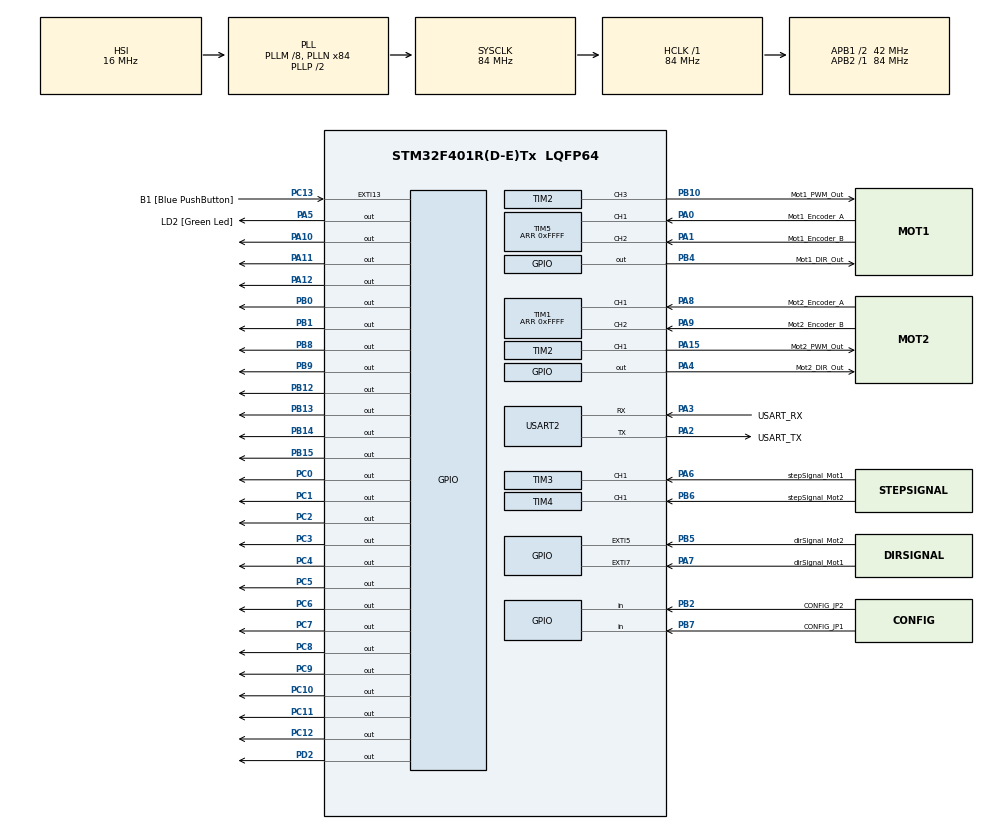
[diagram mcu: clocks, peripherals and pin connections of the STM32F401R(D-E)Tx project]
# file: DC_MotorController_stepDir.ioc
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Dma.Request0=USART2_RX
Dma.USART2_RX.0.Direction=DMA_PERIPH_TO_MEMORY
Dma.USART2_RX.0.FIFOMode=DMA_FIFOMODE_DISABLE
Dma.USART2_RX.0.Instance=DMA1_Stream5
Dma.USART2_RX.0.MemDataAlignment=DMA_MDATAALIGN_BYTE
Dma.USART2_RX.0.MemInc=DMA_MINC_ENABLE
Dma.USART2_RX.0.Mode=DMA_NORMAL
Dma.USART2_RX.0.PeriphDataAlignment=DMA_PDATAALIGN_BYTE
Dma.USART2_RX.0.PeriphInc=DMA_PINC_DISABLE
Dma.USART2_RX.0.Priority=DMA_PRIORITY_LOW
Mcu.Family=STM32F4
Mcu.Name=STM32F401R(D-E)Tx
Mcu.Package=LQFP64
NVIC.DMA1_Stream5_IRQn=true\:0\:0\:false\:false\:true\:false\:true
NVIC.EXTI9_5_IRQn=true\:0\:0\:false\:false\:false\:true\:false
NVIC.PriorityGroup=NVIC_PRIORITYGROUP_4
NVIC.TIM1_UP_TIM10_IRQn=true\:0\:0\:false\:false\:true\:false\:true
NVIC.TimeBase=TIM1_UP_TIM10_IRQn
NVIC.TimeBaseIP=TIM10
PA0-WKUP.GPIO_Label=Mot1_Encoder_A
PA0-WKUP.GPIO_PuPd=GPIO_PULLUP
PA0-WKUP.Signal=S_TIM5_CH1
PA1.GPIO_Label=Mot1_Encoder_B
PA1.GPIO_PuPd=GPIO_PULLUP
PA1.Signal=S_TIM5_CH2
PA10.GPIO_PuPd=GPIO_PULLDOWN
PA10.Signal=GPIO_Output
PA11.GPIO_PuPd=GPIO_PULLDOWN
PA11.Signal=GPIO_Output
PA12.GPIO_PuPd=GPIO_PULLDOWN
PA12.Signal=GPIO_Output
PA13.GPIO_Label=TMS
PA13.Mode=Serial_Wire
PA13.Signal=SYS_JTMS-SWDIO
PA14.GPIO_Label=TCK
PA14.Mode=Serial_Wire
PA14.Signal=SYS_JTCK-SWCLK
PA15.GPIO_Label=Mot2_PWM_Out
PA15.Signal=S_TIM2_CH1_ETR
PA2.GPIO_Label=USART_TX
PA2.GPIO_Mode=GPIO_MODE_AF_PP
PA2.GPIO_PuPd=GPIO_NOPULL
PA2.GPIO_Speed=GPIO_SPEED_FREQ_LOW
PA2.Mode=Asynchronous
PA2.Signal=USART2_TX
PA3.GPIO_Label=USART_RX
PA3.GPIO_Mode=GPIO_MODE_AF_PP
PA3.GPIO_PuPd=GPIO_NOPULL
PA3.GPIO_Speed=GPIO_SPEED_FREQ_LOW
PA3.Mode=Asynchronous
PA3.Signal=USART2_RX
PA4.GPIO_Label=Mot2_DIR_Out
PA4.Signal=GPIO_Output
PA5.GPIO_Label=LD2 [Green Led]
PA5.GPIO_Mode=GPIO_MODE_OUTPUT_PP
PA5.GPIO_PuPd=GPIO_NOPULL
PA5.GPIO_Speed=GPIO_SPEED_FREQ_LOW
PA5.Signal=GPIO_Output
PA6.GPIO_Label=stepSignal_Mot1
PA6.GPIO_PuPd=GPIO_PULLDOWN
PA6.GPIO_Speed=GPIO_SPEED_FREQ_HIGH
PA6.Signal=S_TIM3_CH1
PA7.GPIO_Label=dirSignal_Mot1
PA7.GPIO_ModeDefaultEXTI=GPIO_MODE_IT_RISING_FALLING
PA7.GPIO_PuPd=GPIO_PULLDOWN
PA7.Signal=GPXTI7
PA8.GPIO_Label=Mot2_Encoder_A
PA8.GPIO_PuPd=GPIO_PULLUP
PA8.Signal=S_TIM1_CH1
PA9.GPIO_Label=Mot2_Encoder_B
PA9.GPIO_PuPd=GPIO_PULLUP
PA9.Signal=S_TIM1_CH2
PB0.GPIO_PuPd=GPIO_PULLDOWN
PB0.Signal=GPIO_Output
PB1.GPIO_PuPd=GPIO_PULLDOWN
PB1.Signal=GPIO_Output
PB10.GPIO_Label=Mot1_PWM_Out
PB10.Signal=S_TIM2_CH3
PB12.GPIO_PuPd=GPIO_PULLDOWN
PB12.Signal=GPIO_Output
PB13.GPIO_PuPd=GPIO_PULLDOWN
PB13.Signal=GPIO_Output
PB14.GPIO_PuPd=GPIO_PULLDOWN
PB14.Signal=GPIO_Output
PB15.GPIO_PuPd=GPIO_PULLDOWN
PB15.Signal=GPIO_Output
PB2.GPIO_Label=CONFIG_JP2
PB2.GPIO_PuPd=GPIO_PULLUP
PB2.Signal=GPIO_Input
PB3.GPIO_Label=SWO
PB3.Signal=SYS_JTDO-SWO
PB4.GPIO_Label=Mot1_DIR_Out
PB4.PinState=GPIO_PIN_RESET
PB4.Signal=GPIO_Output
PB5.GPIO_Label=dirSignal_Mot2
PB5.GPIO_ModeDefaultEXTI=GPIO_MODE_IT_RISING_FALLING
PB5.GPIO_PuPd=GPIO_PULLDOWN
PB5.Signal=GPXTI5
PB6.GPIO_Label=stepSignal_Mot2
PB6.GPIO_PuPd=GPIO_PULLDOWN
PB6.GPIO_Speed=GPIO_SPEED_FREQ_HIGH
PB6.Signal=S_TIM4_CH1
PB7.GPIO_Label=CONFIG_JP1
PB7.GPIO_Mode=GPIO_MODE_INPUT
PB7.GPIO_PuPd=GPIO_PULLUP
PB7.Signal=GPIO_Input
PB8.GPIO_PuPd=GPIO_PULLDOWN
PB8.Signal=GPIO_Output
PB9.GPIO_PuPd=GPIO_PULLDOWN
PB9.Signal=GPIO_Output
PC0.GPIO_PuPd=GPIO_PULLDOWN
PC0.Signal=GPIO_Output
PC1.GPIO_PuPd=GPIO_PULLDOWN
PC1.Signal=GPIO_Output
PC10.GPIO_PuPd=GPIO_PULLDOWN
PC10.Signal=GPIO_Output
PC11.GPIO_PuPd=GPIO_PULLDOWN
PC11.Signal=GPIO_Output
PC12.GPIO_PuPd=GPIO_PULLDOWN
PC12.Signal=GPIO_Output
PC13-ANTI_TAMP.GPIO_Label=B1 [Blue PushButton]
PC13-ANTI_TAMP.GPIO_ModeDefaultEXTI=GPIO_MODE_IT_FALLING
PC13-ANTI_TAMP.GPIO_PuPd=GPIO_NOPULL
PC13-ANTI_TAMP.Signal=GPXTI13
PC14-OSC32_IN.Mode=LSE-External-Oscillator
PC14-OSC32_IN.Signal=RCC_OSC32_IN
PC15-OSC32_OUT.Mode=LSE-External-Oscillator
PC15-OSC32_OUT.Signal=RCC_OSC32_OUT
PC2.GPIO_PuPd=GPIO_PULLDOWN
PC2.Signal=GPIO_Output
PC3.GPIO_PuPd=GPIO_PULLDOWN
PC3.Signal=GPIO_Output
PC4.GPIO_PuPd=GPIO_PULLDOWN
PC4.Signal=GPIO_Output
PC5.GPIO_PuPd=GPIO_PULLDOWN
PC5.Signal=GPIO_Output
PC6.GPIO_PuPd=GPIO_PULLDOWN
PC6.Signal=GPIO_Output
PC7.GPIO_PuPd=GPIO_PULLDOWN
PC7.Signal=GPIO_Output
PC8.GPIO_PuPd=GPIO_PULLDOWN
PC8.Signal=GPIO_Output
PC9.GPIO_PuPd=GPIO_PULLDOWN
PC9.Signal=GPIO_Output
PD2.GPIO_PuPd=GPIO_PULLDOWN
PD2.Signal=GPIO_Output
PH0\ -\ OSC_IN.Mode=HSE-External-Clock-Source
PH0\ -\ OSC_IN.Signal=RCC_OSC_IN
PH1\ -\ OSC_OUT.Mode=HSE-External-Clock-Source
PH1\ -\ OSC_OUT.Signal=RCC_OSC_OUT
ProjectManager.HeapSize=0x200
ProjectManager.StackSize=0x400
ProjectManager.TargetToolchain=STM32CubeIDE
RCC.48MHZClocksFreq_Value=24000000
RCC.AHBFreq_Value=84000000
RCC.APB1CLKDivider=RCC_HCLK_DIV2
RCC.APB1Freq_Value=42000000
RCC.APB1TimFreq_Value=84000000
RCC.APB2Freq_Value=84000000
RCC.APB2TimFreq_Value=84000000
RCC.CortexFreq_Value=84000000
RCC.HCLKFreq_Value=84000000
RCC.HSE_VALUE=8000000
RCC.HSI_VALUE=16000000
RCC.PLLM=8
RCC.PLLN=84
RCC.PLLQ=7
RCC.SYSCLKFreq_VALUE=84000000
RCC.SYSCLKSource=RCC_SYSCLKSOURCE_PLLCLK
RCC.VCOOutputFreq_Value=168000000
SH.S_TIM1_CH1.0=TIM1_CH1,Encoder_Interface
SH.S_TIM1_CH2.0=TIM1_CH2,Encoder_Interface
SH.S_TIM2_CH1_ETR.0=TIM2_CH1,PWM Generation1 CH1
SH.S_TIM2_CH3.0=TIM2_CH3,PWM Generation3 CH3
SH.S_TIM3_CH1.0=TIM3_CH1,TriggerSource_TI1FP1
SH.S_TIM4_CH1.0=TIM4_CH1,TriggerSource_TI1FP1
SH.S_TIM5_CH1.0=TIM5_CH1,Encoder_Interface
SH.S_TIM5_CH2.0=TIM5_CH2,Encoder_Interface
TIM1.EncoderMode=TIM_ENCODERMODE_TI12
TIM1.IC1Filter=8
TIM1.IC2Filter=8
TIM1.Period=0xFFFF
TIM2.Channel-PWM\ Generation1\ CH1=TIM_CHANNEL_1
TIM2.Channel-PWM\ Generation3\ CH3=TIM_CHANNEL_3
TIM2.Period=1000-1
TIM2.Prescaler=4-1
TIM3.Period=0xFFFF
TIM3.Slave_TriggerFilter=11
TIM4.Period=0xFFFF
TIM4.Slave_TriggerFilter=11
TIM5.EncoderMode=TIM_ENCODERMODE_TI12
TIM5.IC1Filter=8
TIM5.IC2Filter=8
TIM5.Period=0xFFFF
USART2.VirtualMode=VM_ASYNC
VP_CRC_VS_CRC.Mode=CRC_Activate
VP_SYS_VS_tim10.Mode=TIM10
VP_TIM2_VS_ClockSourceINT.Mode=Internal
VP_TIM3_VS_ControllerModeClock.Mode=Clock Mode
VP_TIM4_VS_ControllerModeClock.Mode=Clock Mode
board=NUCLEO-F401RE

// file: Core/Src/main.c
/* USER CODE BEGIN Header */
/**
  ******************************************************************************
  * @file           : main.c
  * @brief          : Main program body
  ******************************************************************************
  * @attention
  *
  * <h2><center>&copy; Copyright (c) 2020 STMicroelectronics.
  * All rights reserved.</center></h2>
  *
  * This software component is licensed by ST under BSD 3-Clause license,
  * the "License"; You may not use this file except in compliance with the
  * License. You may obtain a copy of the License at:
  *                        opensource.org/licenses/BSD-3-Clause
  *
  ******************************************************************************
  */
/* USER CODE END Header */

#include "main.h"

/* USER CODE BEGIN Includes */
#include <motorTask.h>
//#include <dcMotorController.h>
/* USER CODE END Includes */

CRC_HandleTypeDef hcrc;

TIM_HandleTypeDef htim1;
TIM_HandleTypeDef htim2;
TIM_HandleTypeDef htim3;
TIM_HandleTypeDef htim4;
TIM_HandleTypeDef htim5;

UART_HandleTypeDef huart2;
DMA_HandleTypeDef hdma_usart2_rx;

void SystemClock_Config(void);
static void MX_GPIO_Init(void);
static void MX_DMA_Init(void);
static void MX_USART2_UART_Init(void);
static void MX_CRC_Init(void);
static void MX_TIM1_Init(void);
static void MX_TIM2_Init(void);
static void MX_TIM3_Init(void);
static void MX_TIM4_Init(void);
static void MX_TIM5_Init(void);
/* USER CODE BEGIN PFP */
void EXTI9_5_IRQHandler(void);
/* USER CODE END PFP */

int main(void)
{

  /* MCU Configuration--------------------------------------------------------*/

  /* Reset of all peripherals, Initializes the Flash interface and the Systick. */
  HAL_Init();

  /* Configure the system clock */
  SystemClock_Config();

  /* Initialize all configured peripherals */
  MX_GPIO_Init();
  MX_DMA_Init();
  MX_USART2_UART_Init();
  MX_CRC_Init();
  MX_TIM1_Init();
  MX_TIM2_Init();
  MX_TIM3_Init();
  MX_TIM4_Init();
  MX_TIM5_Init();
  /* USER CODE BEGIN 2 */
  motorInit();
  /* USER CODE END 2 */

  /* Infinite loop */
  /* USER CODE BEGIN WHILE */
  while (1)
  {
	  motorRoutine();
    /* USER CODE END WHILE */

  }
}

void SystemClock_Config(void)
{
  RCC_OscInitTypeDef RCC_OscInitStruct = {0};
  RCC_ClkInitTypeDef RCC_ClkInitStruct = {0};

  /** Configure the main internal regulator output voltage
  */
  __HAL_RCC_PWR_CLK_ENABLE();
  __HAL_PWR_VOLTAGESCALING_CONFIG(PWR_REGULATOR_VOLTAGE_SCALE2);
  /** Initializes the CPU, AHB and APB busses clocks
  */
  RCC_OscInitStruct.OscillatorType = RCC_OSCILLATORTYPE_HSI;
  RCC_OscInitStruct.HSIState = RCC_HSI_ON;
  RCC_OscInitStruct.HSICalibrationValue = RCC_HSICALIBRATION_DEFAULT;
  RCC_OscInitStruct.PLL.PLLState = RCC_PLL_ON;
  RCC_OscInitStruct.PLL.PLLSource = RCC_PLLSOURCE_HSI;
  RCC_OscInitStruct.PLL.PLLM = 8;
  RCC_OscInitStruct.PLL.PLLN = 84;
  RCC_OscInitStruct.PLL.PLLP = RCC_PLLP_DIV2;
  RCC_OscInitStruct.PLL.PLLQ = 7;
  if (HAL_RCC_OscConfig(&RCC_OscInitStruct) != HAL_OK)
  {
    Error_Handler();
  }
  /** Initializes the CPU, AHB and APB busses clocks
  */
  RCC_ClkInitStruct.ClockType = RCC_CLOCKTYPE_HCLK|RCC_CLOCKTYPE_SYSCLK
                              |RCC_CLOCKTYPE_PCLK1|RCC_CLOCKTYPE_PCLK2;
  RCC_ClkInitStruct.SYSCLKSource = RCC_SYSCLKSOURCE_PLLCLK;
  RCC_ClkInitStruct.AHBCLKDivider = RCC_SYSCLK_DIV1;
  RCC_ClkInitStruct.APB1CLKDivider = RCC_HCLK_DIV2;
  RCC_ClkInitStruct.APB2CLKDivider = RCC_HCLK_DIV1;

  if (HAL_RCC_ClockConfig(&RCC_ClkInitStruct, FLASH_LATENCY_2) != HAL_OK)
  {
    Error_Handler();
  }
}

static void MX_CRC_Init(void)
{

  hcrc.Instance = CRC;
  if (HAL_CRC_Init(&hcrc) != HAL_OK)
  {
    Error_Handler();
  }

}

static void MX_TIM1_Init(void)
{

  TIM_Encoder_InitTypeDef sConfig = {0};
  TIM_MasterConfigTypeDef sMasterConfig = {0};

  htim1.Instance = TIM1;
  htim1.Init.Prescaler = 0;
  htim1.Init.CounterMode = TIM_COUNTERMODE_UP;
  htim1.Init.Period = 0xFFFF;
  htim1.Init.ClockDivision = TIM_CLOCKDIVISION_DIV1;
  htim1.Init.RepetitionCounter = 0;
  htim1.Init.AutoReloadPreload = TIM_AUTORELOAD_PRELOAD_DISABLE;
  sConfig.EncoderMode = TIM_ENCODERMODE_TI12;
  sConfig.IC1Polarity = TIM_ICPOLARITY_RISING;
  sConfig.IC1Selection = TIM_ICSELECTION_DIRECTTI;
  sConfig.IC1Prescaler = TIM_ICPSC_DIV1;
  sConfig.IC1Filter = 8;
  sConfig.IC2Polarity = TIM_ICPOLARITY_RISING;
  sConfig.IC2Selection = TIM_ICSELECTION_DIRECTTI;
  sConfig.IC2Prescaler = TIM_ICPSC_DIV1;
  sConfig.IC2Filter = 8;
  if (HAL_TIM_Encoder_Init(&htim1, &sConfig) != HAL_OK)
  {
    Error_Handler();
  }
  sMasterConfig.MasterOutputTrigger = TIM_TRGO_RESET;
  sMasterConfig.MasterSlaveMode = TIM_MASTERSLAVEMODE_DISABLE;
  if (HAL_TIMEx_MasterConfigSynchronization(&htim1, &sMasterConfig) != HAL_OK)
  {
    Error_Handler();
  }

}

static void MX_TIM2_Init(void)
{

  TIM_ClockConfigTypeDef sClockSourceConfig = {0};
  TIM_MasterConfigTypeDef sMasterConfig = {0};
  TIM_OC_InitTypeDef sConfigOC = {0};

  htim2.Instance = TIM2;
  htim2.Init.Prescaler = 4-1;
  htim2.Init.CounterMode = TIM_COUNTERMODE_UP;
  htim2.Init.Period = 1000-1;
  htim2.Init.ClockDivision = TIM_CLOCKDIVISION_DIV1;
  htim2.Init.AutoReloadPreload = TIM_AUTORELOAD_PRELOAD_DISABLE;
  if (HAL_TIM_Base_Init(&htim2) != HAL_OK)
  {
    Error_Handler();
  }
  sClockSourceConfig.ClockSource = TIM_CLOCKSOURCE_INTERNAL;
  if (HAL_TIM_ConfigClockSource(&htim2, &sClockSourceConfig) != HAL_OK)
  {
    Error_Handler();
  }
  if (HAL_TIM_PWM_Init(&htim2) != HAL_OK)
  {
    Error_Handler();
  }
  sMasterConfig.MasterOutputTrigger = TIM_TRGO_RESET;
  sMasterConfig.MasterSlaveMode = TIM_MASTERSLAVEMODE_DISABLE;
  if (HAL_TIMEx_MasterConfigSynchronization(&htim2, &sMasterConfig) != HAL_OK)
  {
    Error_Handler();
  }
  sConfigOC.OCMode = TIM_OCMODE_PWM1;
  sConfigOC.Pulse = 0;
  sConfigOC.OCPolarity = TIM_OCPOLARITY_HIGH;
  sConfigOC.OCFastMode = TIM_OCFAST_DISABLE;
  if (HAL_TIM_PWM_ConfigChannel(&htim2, &sConfigOC, TIM_CHANNEL_1) != HAL_OK)
  {
    Error_Handler();
  }
  if (HAL_TIM_PWM_ConfigChannel(&htim2, &sConfigOC, TIM_CHANNEL_3) != HAL_OK)
  {
    Error_Handler();
  }
  HAL_TIM_MspPostInit(&htim2);

}

static void MX_TIM3_Init(void)
{

  TIM_SlaveConfigTypeDef sSlaveConfig = {0};
  TIM_MasterConfigTypeDef sMasterConfig = {0};

  htim3.Instance = TIM3;
  htim3.Init.Prescaler = 0;
  htim3.Init.CounterMode = TIM_COUNTERMODE_UP;
  htim3.Init.Period = 0xFFFF;
  htim3.Init.ClockDivision = TIM_CLOCKDIVISION_DIV1;
  htim3.Init.AutoReloadPreload = TIM_AUTORELOAD_PRELOAD_DISABLE;
  if (HAL_TIM_Base_Init(&htim3) != HAL_OK)
  {
    Error_Handler();
  }
  sSlaveConfig.SlaveMode = TIM_SLAVEMODE_EXTERNAL1;
  sSlaveConfig.InputTrigger = TIM_TS_TI1FP1;
  sSlaveConfig.TriggerPolarity = TIM_TRIGGERPOLARITY_RISING;
  sSlaveConfig.TriggerFilter = 11;
  if (HAL_TIM_SlaveConfigSynchro(&htim3, &sSlaveConfig) != HAL_OK)
  {
    Error_Handler();
  }
  sMasterConfig.MasterOutputTrigger = TIM_TRGO_RESET;
  sMasterConfig.MasterSlaveMode = TIM_MASTERSLAVEMODE_DISABLE;
  if (HAL_TIMEx_MasterConfigSynchronization(&htim3, &sMasterConfig) != HAL_OK)
  {
    Error_Handler();
  }

}

static void MX_TIM4_Init(void)
{

  TIM_SlaveConfigTypeDef sSlaveConfig = {0};
  TIM_MasterConfigTypeDef sMasterConfig = {0};

  htim4.Instance = TIM4;
  htim4.Init.Prescaler = 0;
  htim4.Init.CounterMode = TIM_COUNTERMODE_UP;
  htim4.Init.Period = 0xFFFF;
  htim4.Init.ClockDivision = TIM_CLOCKDIVISION_DIV1;
  htim4.Init.AutoReloadPreload = TIM_AUTORELOAD_PRELOAD_DISABLE;
  if (HAL_TIM_Base_Init(&htim4) != HAL_OK)
  {
    Error_Handler();
  }
  sSlaveConfig.SlaveMode = TIM_SLAVEMODE_EXTERNAL1;
  sSlaveConfig.InputTrigger = TIM_TS_TI1FP1;
  sSlaveConfig.TriggerPolarity = TIM_TRIGGERPOLARITY_RISING;
  sSlaveConfig.TriggerFilter = 11;
  if (HAL_TIM_SlaveConfigSynchro(&htim4, &sSlaveConfig) != HAL_OK)
  {
    Error_Handler();
  }
  sMasterConfig.MasterOutputTrigger = TIM_TRGO_RESET;
  sMasterConfig.MasterSlaveMode = TIM_MASTERSLAVEMODE_DISABLE;
  if (HAL_TIMEx_MasterConfigSynchronization(&htim4, &sMasterConfig) != HAL_OK)
  {
    Error_Handler();
  }

}

static void MX_TIM5_Init(void)
{

  TIM_Encoder_InitTypeDef sConfig = {0};
  TIM_MasterConfigTypeDef sMasterConfig = {0};

  htim5.Instance = TIM5;
  htim5.Init.Prescaler = 0;
  htim5.Init.CounterMode = TIM_COUNTERMODE_UP;
  htim5.Init.Period = 0xFFFF;
  htim5.Init.ClockDivision = TIM_CLOCKDIVISION_DIV1;
  htim5.Init.AutoReloadPreload = TIM_AUTORELOAD_PRELOAD_DISABLE;
  sConfig.EncoderMode = TIM_ENCODERMODE_TI12;
  sConfig.IC1Polarity = TIM_ICPOLARITY_RISING;
  sConfig.IC1Selection = TIM_ICSELECTION_DIRECTTI;
  sConfig.IC1Prescaler = TIM_ICPSC_DIV1;
  sConfig.IC1Filter = 8;
  sConfig.IC2Polarity = TIM_ICPOLARITY_RISING;
  sConfig.IC2Selection = TIM_ICSELECTION_DIRECTTI;
  sConfig.IC2Prescaler = TIM_ICPSC_DIV1;
  sConfig.IC2Filter = 8;
  if (HAL_TIM_Encoder_Init(&htim5, &sConfig) != HAL_OK)
  {
    Error_Handler();
  }
  sMasterConfig.MasterOutputTrigger = TIM_TRGO_RESET;
  sMasterConfig.MasterSlaveMode = TIM_MASTERSLAVEMODE_DISABLE;
  if (HAL_TIMEx_MasterConfigSynchronization(&htim5, &sMasterConfig) != HAL_OK)
  {
    Error_Handler();
  }

}

static void MX_USART2_UART_Init(void)
{

  huart2.Instance = USART2;
  huart2.Init.BaudRate = 115200;
  huart2.Init.WordLength = UART_WORDLENGTH_8B;
  huart2.Init.StopBits = UART_STOPBITS_1;
  huart2.Init.Parity = UART_PARITY_NONE;
  huart2.Init.Mode = UART_MODE_TX_RX;
  huart2.Init.HwFlowCtl = UART_HWCONTROL_NONE;
  huart2.Init.OverSampling = UART_OVERSAMPLING_16;
  if (HAL_UART_Init(&huart2) != HAL_OK)
  {
    Error_Handler();
  }

}

static void MX_DMA_Init(void)
{

  /* DMA controller clock enable */
  __HAL_RCC_DMA1_CLK_ENABLE();

  /* DMA interrupt init */
  /* DMA1_Stream5_IRQn interrupt configuration */
  HAL_NVIC_SetPriority(DMA1_Stream5_IRQn, 0, 0);
  HAL_NVIC_EnableIRQ(DMA1_Stream5_IRQn);

}

static void MX_GPIO_Init(void)
{
  GPIO_InitTypeDef GPIO_InitStruct = {0};

  /* GPIO Ports Clock Enable */
  __HAL_RCC_GPIOC_CLK_ENABLE();
  __HAL_RCC_GPIOH_CLK_ENABLE();
  __HAL_RCC_GPIOA_CLK_ENABLE();
  __HAL_RCC_GPIOB_CLK_ENABLE();
  __HAL_RCC_GPIOD_CLK_ENABLE();

  /*Configure GPIO pin Output Level */
  HAL_GPIO_WritePin(GPIOC, GPIO_PIN_0|GPIO_PIN_1|GPIO_PIN_2|GPIO_PIN_3
                          |GPIO_PIN_4|GPIO_PIN_5|GPIO_PIN_6|GPIO_PIN_7
                          |GPIO_PIN_8|GPIO_PIN_9|GPIO_PIN_10|GPIO_PIN_11
                          |GPIO_PIN_12, GPIO_PIN_RESET);

  /*Configure GPIO pin Output Level */
  HAL_GPIO_WritePin(GPIOA, Mot2_DIR_Out_Pin|LD2_Pin|GPIO_PIN_10|GPIO_PIN_11
                          |GPIO_PIN_12, GPIO_PIN_RESET);

  /*Configure GPIO pin Output Level */
  HAL_GPIO_WritePin(GPIOB, GPIO_PIN_0|GPIO_PIN_1|GPIO_PIN_12|GPIO_PIN_13
                          |GPIO_PIN_14|GPIO_PIN_15|Mot1_DIR_Out_Pin|GPIO_PIN_8
                          |GPIO_PIN_9, GPIO_PIN_RESET);

  /*Configure GPIO pin Output Level */
  HAL_GPIO_WritePin(GPIOD, GPIO_PIN_2, GPIO_PIN_RESET);

  /*Configure GPIO pin : B1_Pin */
  GPIO_InitStruct.Pin = B1_Pin;
  GPIO_InitStruct.Mode = GPIO_MODE_IT_FALLING;
  GPIO_InitStruct.Pull = GPIO_NOPULL;
  HAL_GPIO_Init(B1_GPIO_Port, &GPIO_InitStruct);

  /*Configure GPIO pins : PC0 PC1 PC2 PC3
                           PC4 PC5 PC6 PC7
                           PC8 PC9 PC10 PC11
                           PC12 */
  GPIO_InitStruct.Pin = GPIO_PIN_0|GPIO_PIN_1|GPIO_PIN_2|GPIO_PIN_3
                          |GPIO_PIN_4|GPIO_PIN_5|GPIO_PIN_6|GPIO_PIN_7
                          |GPIO_PIN_8|GPIO_PIN_9|GPIO_PIN_10|GPIO_PIN_11
                          |GPIO_PIN_12;
  GPIO_InitStruct.Mode = GPIO_MODE_OUTPUT_PP;
  GPIO_InitStruct.Pull = GPIO_PULLDOWN;
  GPIO_InitStruct.Speed = GPIO_SPEED_FREQ_LOW;
  HAL_GPIO_Init(GPIOC, &GPIO_InitStruct);

  /*Configure GPIO pins : Mot2_DIR_Out_Pin LD2_Pin */
  GPIO_InitStruct.Pin = Mot2_DIR_Out_Pin|LD2_Pin;
  GPIO_InitStruct.Mode = GPIO_MODE_OUTPUT_PP;
  GPIO_InitStruct.Pull = GPIO_NOPULL;
  GPIO_InitStruct.Speed = GPIO_SPEED_FREQ_LOW;
  HAL_GPIO_Init(GPIOA, &GPIO_InitStruct);

  /*Configure GPIO pin : dirSignal_Mot1_Pin */
  GPIO_InitStruct.Pin = dirSignal_Mot1_Pin;
  GPIO_InitStruct.Mode = GPIO_MODE_IT_RISING_FALLING;
  GPIO_InitStruct.Pull = GPIO_PULLDOWN;
  HAL_GPIO_Init(dirSignal_Mot1_GPIO_Port, &GPIO_InitStruct);

  /*Configure GPIO pins : PB0 PB1 PB12 PB13
                           PB14 PB15 PB8 PB9 */
  GPIO_InitStruct.Pin = GPIO_PIN_0|GPIO_PIN_1|GPIO_PIN_12|GPIO_PIN_13
                          |GPIO_PIN_14|GPIO_PIN_15|GPIO_PIN_8|GPIO_PIN_9;
  GPIO_InitStruct.Mode = GPIO_MODE_OUTPUT_PP;
  GPIO_InitStruct.Pull = GPIO_PULLDOWN;
  GPIO_InitStruct.Speed = GPIO_SPEED_FREQ_LOW;
  HAL_GPIO_Init(GPIOB, &GPIO_InitStruct);

  /*Configure GPIO pins : CONFIG_JP2_Pin CONFIG_JP1_Pin */
  GPIO_InitStruct.Pin = CONFIG_JP2_Pin|CONFIG_JP1_Pin;
  GPIO_InitStruct.Mode = GPIO_MODE_INPUT;
  GPIO_InitStruct.Pull = GPIO_PULLUP;
  HAL_GPIO_Init(GPIOB, &GPIO_InitStruct);

  /*Configure GPIO pins : PA10 PA11 PA12 */
  GPIO_InitStruct.Pin = GPIO_PIN_10|GPIO_PIN_11|GPIO_PIN_12;
  GPIO_InitStruct.Mode = GPIO_MODE_OUTPUT_PP;
  GPIO_InitStruct.Pull = GPIO_PULLDOWN;
  GPIO_InitStruct.Speed = GPIO_SPEED_FREQ_LOW;
  HAL_GPIO_Init(GPIOA, &GPIO_InitStruct);

  /*Configure GPIO pin : PD2 */
  GPIO_InitStruct.Pin = GPIO_PIN_2;
  GPIO_InitStruct.Mode = GPIO_MODE_OUTPUT_PP;
  GPIO_InitStruct.Pull = GPIO_PULLDOWN;
  GPIO_InitStruct.Speed = GPIO_SPEED_FREQ_LOW;
  HAL_GPIO_Init(GPIOD, &GPIO_InitStruct);

  /*Configure GPIO pin : Mot1_DIR_Out_Pin */
  GPIO_InitStruct.Pin = Mot1_DIR_Out_Pin;
  GPIO_InitStruct.Mode = GPIO_MODE_OUTPUT_PP;
  GPIO_InitStruct.Pull = GPIO_NOPULL;
  GPIO_InitStruct.Speed = GPIO_SPEED_FREQ_LOW;
  HAL_GPIO_Init(Mot1_DIR_Out_GPIO_Port, &GPIO_InitStruct);

  /*Configure GPIO pin : dirSignal_Mot2_Pin */
  GPIO_InitStruct.Pin = dirSignal_Mot2_Pin;
  GPIO_InitStruct.Mode = GPIO_MODE_IT_RISING_FALLING;
  GPIO_InitStruct.Pull = GPIO_PULLDOWN;
  HAL_GPIO_Init(dirSignal_Mot2_GPIO_Port, &GPIO_InitStruct);

  /* EXTI interrupt init*/
  HAL_NVIC_SetPriority(EXTI9_5_IRQn, 0, 0);
  HAL_NVIC_EnableIRQ(EXTI9_5_IRQn);

}

/* USER CODE BEGIN 4 */
void EXTI9_5_IRQHandler(void) {
	toggleCounterDirections();
}
/* USER CODE END 4 */

 /**
  * @brief  Period elapsed callback in non blocking mode
  * @note   This function is called  when TIM10 interrupt took place, inside
  * HAL_TIM_IRQHandler(). It makes a direct call to HAL_IncTick() to increment
  * a global variable "uwTick" used as application time base.
  * @param  htim : TIM handle
  * @retval None
  */
void HAL_TIM_PeriodElapsedCallback(TIM_HandleTypeDef *htim)
{
  if (htim->Instance == TIM10) {
    HAL_IncTick();
  }
}

void Error_Handler(void)
{
  /* USER CODE BEGIN Error_Handler_Debug */
  /* User can add his own implementation to report the HAL error return state */
  // Ensure LD2_GPIO_Port clock is enabled (usually done in HAL_Init or HAL_MspInit)
  // For Nucleo-F401RE, LD2 is on PA5. GPIOA clock must be enabled.
  // This is typically handled by MX_GPIO_Init calling __HAL_RCC_GPIOA_CLK_ENABLE().
  // MX_GPIO_Init() also configures LD2_Pin as output.

  // Turn on LD2 (User LED) to indicate an error
  HAL_GPIO_WritePin(LD2_GPIO_Port, LD2_Pin, GPIO_PIN_SET);

  // Disable all interrupts to prevent further operations from interfering
  __disable_irq();

  // Enter an infinite loop to halt the system.
  // This makes the error state persistent and observable.
  while (1)
  {
    // Loop indefinitely
  }
  /* USER CODE END Error_Handler_Debug */
}

/************************ (C) COPYRIGHT STMicroelectronics *****END OF FILE****/
